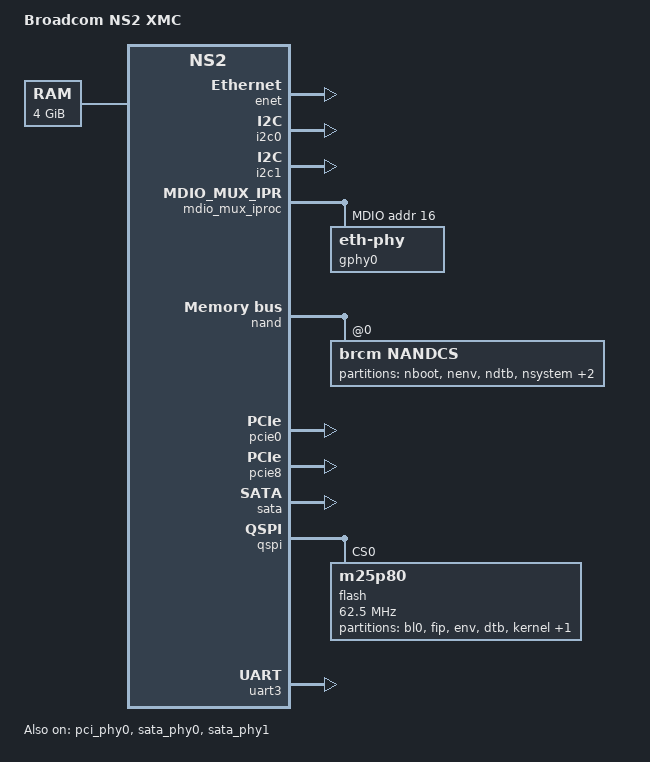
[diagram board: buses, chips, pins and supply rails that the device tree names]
/dts-v1/;
#include "ns2.dtsi"
/ {
	model = "Broadcom NS2 XMC";
	compatible = "brcm,ns2-xmc", "brcm,ns2";
	aliases {
		serial0 = &uart3;
	};
	chosen {
		stdout-path = "serial0:115200n8";
		bootargs = "earlycon=uart8250,mmio32,0x66130000";
	};
	memory {
		device_type = "memory";
		reg = <0x00000000 0x80000000 0x00000001 0x00000000>;
	};
};
&enet {
	status = "okay";
};
&i2c0 {
	status = "okay";
};
&i2c1 {
	status = "okay";
};
&mdio_mux_iproc {
	mdio@10 {
		gphy0: eth-phy@10 {
			reg = <0x10>;
		};
	};
};
&nand {
	nandcs@0 {
		compatible = "brcm,nandcs";
		reg = <0>;
		nand-ecc-mode = "hw";
		nand-ecc-strength = <8>;
		nand-ecc-step-size = <512>;
		nand-bus-width = <16>;
		brcm,nand-oob-sector-size = <16>;
		#address-cells = <1>;
		#size-cells = <1>;
		partition@0 {
			label = "nboot";
			reg = <0x00000000 0x00280000>;  
			read-only;
		};
		partition@280000 {
			label = "nenv";
			reg = <0x00280000 0x00040000>;  
			read-only;
		};
		partition@2c0000 {
			label = "ndtb";
			reg = <0x002c0000 0x00040000>;  
			read-only;
		};
		partition@300000 {
			label = "nsystem";
			reg = <0x00300000 0x03d00000>;  
			read-only;
		};
		partition@4000000 {
			label = "nrootfs";
			reg = <0x04000000 0x06400000>;  
		};
		partition@a400000 {
			label = "ncustfs";
			reg = <0x0a400000 0x35c00000>;  
		};
	};
};
&pci_phy0 {
	status = "okay";
};
&pcie0 {
	status = "okay";
};
&pcie8 {
	status = "okay";
};
&sata_phy0 {
	status = "okay";
};
&sata_phy1 {
	status = "okay";
};
&sata {
	status = "okay";
};
&qspi {
	flash: flash@0 {
		#address-cells = <1>;
		#size-cells = <1>;
		compatible = "m25p80";
		spi-max-frequency = <62500000>;
		m25p,default-addr-width = <3>;
		reg = <0x0 0x0>;
		partition@0 {
			label = "bl0";
			reg = <0x00000000 0x00080000>;  
		};
		partition@80000 {
			label = "fip";
			reg = <0x00080000 0x00150000>;  
		};
		partition@1e0000 {
			label = "env";
			reg = <0x001e0000 0x00010000>; 
		};
		partition@1f0000 {
			label = "dtb";
			reg = <0x001f0000 0x00010000>;  
		};
		partition@200000 {
			label = "kernel";
			reg = <0x00200000 0x00e00000>;  
		};
		partition@1000000 {
			label = "rootfs";
			reg = <0x01000000 0x01000000>;  
		};
	};
};
&uart3 {
	status = "okay";
};
